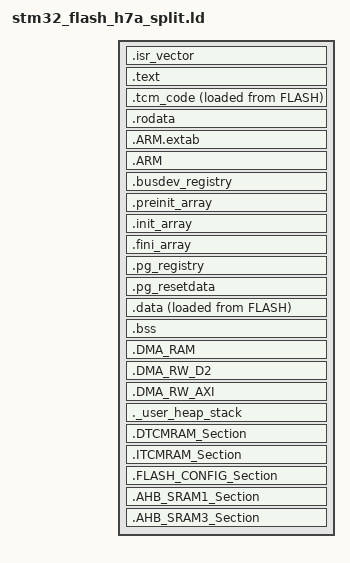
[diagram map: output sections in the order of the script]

/*
*****************************************************************************
**
**  File        : stm32_flash_split.ld
**
**  Abstract    : Common linker script for STM32 devices.
**
*****************************************************************************
*/

/* Entry Point */
ENTRY(Reset_Handler)

/* Highest address of the user mode stack */
_estack = ORIGIN(STACKRAM) + LENGTH(STACKRAM);    /* end of RAM */

/* Base address where the config is stored. */
__config_start = ORIGIN(FLASH_CONFIG);
__config_end = ORIGIN(FLASH_CONFIG) + LENGTH(FLASH_CONFIG);

/* Define output sections */
SECTIONS
{
  /* The startup code goes first into FLASH */
  .isr_vector :
  {
    . = ALIGN(4);
    KEEP(*(.isr_vector)) /* Startup code */
    . = ALIGN(4);
  } >FLASH

  /* The program code and other data goes into FLASH */
  .text :
  {
    . = ALIGN(4);
    *(.text)           /* .text sections (code) */
    *(.text*)          /* .text* sections (code) */
    *(.glue_7)         /* glue arm to thumb code */
    *(.glue_7t)        /* glue thumb to arm code */
    *(.eh_frame)

    KEEP (*(.init))
    KEEP (*(.fini))

    . = ALIGN(4);
    _etext = .;        /* define a global symbols at end of code */
  } >FLASH

  tcm_code = LOADADDR(.tcm_code); 
  .tcm_code (NOLOAD) :
  {
    . = ALIGN(4);
    tcm_code_start = .; 
    *(.tcm_code)
    *(.tcm_code*)
    . = ALIGN(4);
    tcm_code_end = .; 
  } >ITCMRAM AT >FLASH

  /* Constant data goes into FLASH */
  .rodata :
  {
    . = ALIGN(4);
    *(.rodata)         /* .rodata sections (constants, strings, etc.) */
    *(.rodata*)        /* .rodata* sections (constants, strings, etc.) */
    . = ALIGN(4);
  } >FLASH

  .ARM.extab   : { *(.ARM.extab* .gnu.linkonce.armextab.*) } >FLASH
  .ARM : {
    __exidx_start = .;
    *(.ARM.exidx*)
    __exidx_end = .;
  } >FLASH

  .busdev_registry :
  {
    PROVIDE_HIDDEN (__busdev_registry_start = .);
    KEEP (*(.busdev_registry))
    KEEP (*(SORT(.busdev_registry.*)))
    PROVIDE_HIDDEN (__busdev_registry_end = .);
  } >FLASH

  .preinit_array     :
  {
    PROVIDE_HIDDEN (__preinit_array_start = .);
    KEEP (*(.preinit_array*))
    PROVIDE_HIDDEN (__preinit_array_end = .);
  } >FLASH
  .init_array :
  {
    PROVIDE_HIDDEN (__init_array_start = .);
    KEEP (*(SORT(.init_array.*)))
    KEEP (*(.init_array*))
    PROVIDE_HIDDEN (__init_array_end = .);
  } >FLASH
  .fini_array :
  {
    PROVIDE_HIDDEN (__fini_array_start = .);
    KEEP (*(SORT(.fini_array.*)))
    KEEP (*(.fini_array*))
    PROVIDE_HIDDEN (__fini_array_end = .);
  } >FLASH
  .pg_registry :
  {
    PROVIDE_HIDDEN (__pg_registry_start = .);
    KEEP (*(.pg_registry))
    KEEP (*(SORT(.pg_registry.*)))
    PROVIDE_HIDDEN (__pg_registry_end = .);
  } >FLASH
  .pg_resetdata :
  {
    PROVIDE_HIDDEN (__pg_resetdata_start = .);
    KEEP (*(.pg_resetdata))
    PROVIDE_HIDDEN (__pg_resetdata_end = .);
  } >FLASH

  /* used by the startup to initialize data */
  _sidata = LOADADDR(.data);

  /* Initialized data sections goes into RAM, load LMA copy after code */
  .data : 
  {
    . = ALIGN(4);
    _sdata = .;        /* create a global symbol at data start */
    *(.data)           /* .data sections */
    *(.data*)          /* .data* sections */

    . = ALIGN(4);
    _edata = .;        /* define a global symbol at data end */
  } >RAM AT> FLASH

  
  /* Uninitialized data section */
  . = ALIGN(4);
  .bss :
  {
    /* This is used by the startup in order to initialize the .bss secion */
    _sbss = .;         /* define a global symbol at bss start */
    __bss_start__ = _sbss;
    *(.bss)
    *(.bss*)
    *(COMMON)

    . = ALIGN(4);
    _ebss = .;         /* define a global symbol at bss end */
    __bss_end__ = _ebss;
  } >RAM

  .DMA_RAM (NOLOAD) :
  {
    . = ALIGN(32);
    PROVIDE(dmaram_start = .);
    _sdmaram = .;
    _dmaram_start__ = _sdmaram;
    KEEP(*(.DMA_RAM))
    PROVIDE(dmaram_end = .);
    _edmaram = .;
    _dmaram_end__ = _edmaram;
  } >D2_RAM

  .DMA_RW_D2 (NOLOAD) :
  {
    . = ALIGN(32);
    PROVIDE(dmarw_start = .);
    _sdmarw = .;
    _dmarw_start__ = _sdmarw;
    KEEP(*(.DMA_RW))
    PROVIDE(dmarw_end = .);
    _edmarw = .;
    _dmarw_end__ = _edmarw;
  } >D2_RAM

  .DMA_RW_AXI (NOLOAD) :
  {
    . = ALIGN(32);
    PROVIDE(dmarwaxi_start = .);
    _sdmarwaxi = .;
    _dmarwaxi_start__ = _sdmarwaxi;
    KEEP(*(.DMA_RW_AXI))
    PROVIDE(dmarwaxi_end = .);
    _edmarwaxi = .;
    _dmarwaxi_end__ = _edmarwaxi;
  } >RAM



  /* User_heap_stack section, used to check that there is enough RAM left */
  ._user_heap_stack :
  {
    . = ALIGN(8);
    PROVIDE ( end = . );
    PROVIDE ( _end = . );
    . = . + _Min_Heap_Size;
    . = . + _Min_Stack_Size;
    . = ALIGN(8);
  } >RAM

  

  /* Remove information from the standard libraries */
  /DISCARD/ :
  {
    libc.a ( * )
    libm.a ( * )
    libgcc.a ( * )
  }

/*Start of  Sections- Auto-generated By STM32CubeMX*/
.DTCMRAM_Section :
{. = ALIGN(4);
KEEP (*(.DTCMRAM_Section ))
. = ALIGN(4);
} >DTCMRAM
.ITCMRAM_Section :
{. = ALIGN(4);
KEEP (*(.ITCMRAM_Section ))
. = ALIGN(4);
} >ITCMRAM
.FLASH_CONFIG_Section :
{. = ALIGN(4);
KEEP (*(.FLASH_CONFIG_Section ))
. = ALIGN(4);
} >FLASH_CONFIG
.AHB_SRAM1_Section :
{. = ALIGN(4);
KEEP (*(.AHB_SRAM1_Section ))
. = ALIGN(4);
} >AHB_SRAM1
/*
.AHB_SRAM2_Section :
{. = ALIGN(4);
KEEP (*(.AHB_SRAM2_Section ))
. = ALIGN(4);
} >AHB_SRAM2
*/
.AHB_SRAM3_Section :
{. = ALIGN(4);
KEEP (*(.AHB_SRAM3_Section ))
. = ALIGN(4);
} >AHB_SRAM3
}

